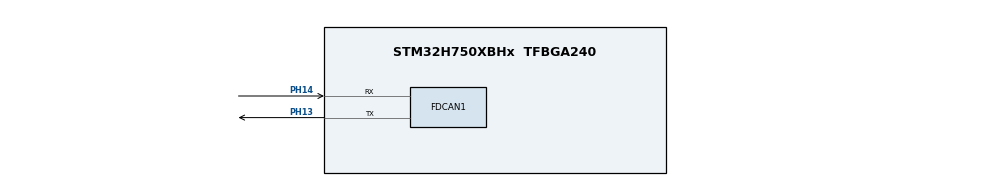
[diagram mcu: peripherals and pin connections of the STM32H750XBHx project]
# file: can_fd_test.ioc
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FDCAN1.AutoRetransmission=DISABLE
FDCAN1.CalculateBaudRateNominal=500000
FDCAN1.CalculateTimeBitNominal=2000
FDCAN1.CalculateTimeQuantumNominal=20.0
FDCAN1.DataPrescaler=2
FDCAN1.DataSyncJumpWidth=5
FDCAN1.DataTimeSeg1=19
FDCAN1.DataTimeSeg2=5
FDCAN1.FrameFormat=FDCAN_FRAME_FD_BRS
FDCAN1.Mode=FDCAN_MODE_EXTERNAL_LOOPBACK
FDCAN1.NominalPrescaler=1
FDCAN1.NominalSyncJumpWidth=13
FDCAN1.NominalTimeSeg1=86
FDCAN1.NominalTimeSeg2=13
FDCAN1.RxBufferSize=FDCAN_DATA_BYTES_12
FDCAN1.RxBuffersNbr=2
FDCAN1.RxFifo0ElmtSize=FDCAN_DATA_BYTES_12
FDCAN1.RxFifo0ElmtsNbr=1
FDCAN1.RxFifo1ElmtSize=FDCAN_DATA_BYTES_12
FDCAN1.RxFifo1ElmtsNbr=1
FDCAN1.StdFiltersNbr=10
FDCAN1.TransmitPause=ENABLE
FDCAN1.TxBuffersNbr=5
FDCAN1.TxElmtSize=FDCAN_DATA_BYTES_12
Mcu.Family=STM32H7
Mcu.Name=STM32H750XBHx
Mcu.Package=TFBGA240
NVIC.FDCAN1_IT0_IRQn=true\:0\:0\:false\:false\:true\:true\:true\:true
NVIC.FDCAN1_IT1_IRQn=true\:0\:0\:false\:false\:true\:true\:true\:true
NVIC.PriorityGroup=NVIC_PRIORITYGROUP_4
PB13.Signal=FDCAN2_TX
PH0-OSC_IN\ (PH0).Mode=HSE-External-Oscillator
PH0-OSC_IN\ (PH0).Signal=RCC_OSC_IN
PH1-OSC_OUT\ (PH1).Mode=HSE-External-Oscillator
PH1-OSC_OUT\ (PH1).Signal=RCC_OSC_OUT
PH13.Mode=FDCAN_Activate
PH13.Signal=FDCAN1_TX
PH14.Mode=FDCAN_Activate
PH14.Signal=FDCAN1_RX
ProjectManager.HeapSize=0x200
ProjectManager.StackSize=0x400
ProjectManager.TargetToolchain=STM32CubeIDE
RCC.ADCFreq_Value=80000000
RCC.APB1Freq_Value=100000000
RCC.APB2Freq_Value=100000000
RCC.APB3Freq_Value=100000000
RCC.APB4Freq_Value=100000000
RCC.CortexFreq_Value=400000000
RCC.D1PPRE=RCC_APB3_DIV2
RCC.D2PPRE1=RCC_APB1_DIV2
RCC.D2PPRE2=RCC_APB2_DIV2
RCC.D3PPRE=RCC_APB4_DIV2
RCC.DIVM1=2
RCC.DIVM2=5
RCC.DIVN1=64
RCC.DIVN2=32
RCC.DIVQ1=16
RCC.HCLKFreq_Value=200000000
RCC.HPRE=RCC_HCLK_DIV2
RCC.HSE_VALUE=25000000
RCC.PLL2FRACN=0
RCC.PLL3FRACN=0
RCC.PLLFRACN=0
RCC.PLLSourceVirtual=RCC_PLLSOURCE_HSE
RCC.SYSCLKFreq_VALUE=400000000
RCC.SYSCLKSource=RCC_SYSCLKSOURCE_PLLCLK
RCC.USBFreq_Value=50000000
VP_MEMORYMAP_VS_MEMORYMAP.Mode=CurAppReg
board=custom

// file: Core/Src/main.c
/* USER CODE BEGIN Header */
/**
  ******************************************************************************
  * @file           : main.c
  * @brief          : Main program body
  ******************************************************************************
  * @attention
  *
  * Copyright (c) 2024 STMicroelectronics.
  * All rights reserved.
  *
  * This software is licensed under terms that can be found in the LICENSE file
  * in the root directory of this software component.
  * If no LICENSE file comes with this software, it is provided AS-IS.
  *
  ******************************************************************************
  */
/* USER CODE END Header */
#include "main.h"
#include "fdcan.h"
#include "memorymap.h"
#include "gpio.h"

void SystemClock_Config(void);

/* USER CODE BEGIN 0 */
#define DEF_TX_DATA_LENGTH (12U)
FDCAN_FilterTypeDef sFilterConfig;
FDCAN_TxHeaderTypeDef TxHeader;
FDCAN_RxHeaderTypeDef RxHeader;
uint8_t TxData[DEF_TX_DATA_LENGTH] = {0x01, 0x02, 0x03, 0x04, 0x05, 0x06, 0x07, 0x08, 0x09, 0x0A, 0x0B, 0x0C};
uint8_t RxData_0[12];
uint8_t RxData_1[12];
uint8_t RxData_FIFO_0[12];
uint8_t new_buff_flag = 0;
uint8_t new_fifo_0_flag = 0;
uint8_t new_fifo_1_flag = 0;

uint8_t rx_data_ok = 0;
uint8_t rx_remote_ok = 0;
uint8_t rx_fifo_range_ok = 0;
uint8_t rx_fifo_mask_ok = 0;

void filterSet(void);
void txBufferSet(void);
void notificationSet(void);
void txbufferStart(void);
void newMessageCheckLoop(void);
/* USER CODE END 0 */

int main(void)
{

  /* MCU Configuration--------------------------------------------------------*/

  /* Reset of all peripherals, Initializes the Flash interface and the Systick. */
  HAL_Init();

  /* Configure the system clock */
  SystemClock_Config();

  /* Initialize all configured peripherals */
  MX_GPIO_Init();
  MX_FDCAN1_Init();
  /* USER CODE BEGIN 2 */
  /* USER CODE BEGIN 2 */
  filterSet();
  txBufferSet();

  HAL_FDCAN_Start(&hfdcan1);

  notificationSet();
  txbufferStart();

  /* USER CODE END 2 */

  /* Infinite loop */
  while (1)
  {

    /* USER CODE BEGIN 3 */
	  newMessageCheckLoop();
	  if(rx_data_ok == 1
	  			  && rx_remote_ok == 1
	  			  && rx_fifo_range_ok == 1)
	  {
		  rx_data_ok = 0;
		  rx_remote_ok = 0;
		  rx_fifo_range_ok = 0;
		  txbufferStart();
	  }
	  // mask error
//	  if(rx_data_ok == 1
//			  && rx_remote_ok == 1
//			  && rx_fifo_range_ok == 1
//			  && rx_fifo_mask_ok == 1)
//	  {
//		  rx_data_ok = 0;
//		  rx_remote_ok = 0;
//		  rx_fifo_range_ok = 0;
//		  rx_fifo_mask_ok = 0;
//		  txbufferStart();
//	  }
  }
  /* USER CODE END 3 */
}

void SystemClock_Config(void)
{
  RCC_OscInitTypeDef RCC_OscInitStruct = {0};
  RCC_ClkInitTypeDef RCC_ClkInitStruct = {0};

  /** Supply configuration update enable
  */
  HAL_PWREx_ConfigSupply(PWR_LDO_SUPPLY);

  /** Configure the main internal regulator output voltage
  */
  __HAL_PWR_VOLTAGESCALING_CONFIG(PWR_REGULATOR_VOLTAGE_SCALE1);

  while(!__HAL_PWR_GET_FLAG(PWR_FLAG_VOSRDY)) {}

  /** Initializes the RCC Oscillators according to the specified parameters
  * in the RCC_OscInitTypeDef structure.
  */
  RCC_OscInitStruct.OscillatorType = RCC_OSCILLATORTYPE_HSE;
  RCC_OscInitStruct.HSEState = RCC_HSE_ON;
  RCC_OscInitStruct.PLL.PLLState = RCC_PLL_ON;
  RCC_OscInitStruct.PLL.PLLSource = RCC_PLLSOURCE_HSE;
  RCC_OscInitStruct.PLL.PLLM = 2;
  RCC_OscInitStruct.PLL.PLLN = 64;
  RCC_OscInitStruct.PLL.PLLP = 2;
  RCC_OscInitStruct.PLL.PLLQ = 16;
  RCC_OscInitStruct.PLL.PLLR = 2;
  RCC_OscInitStruct.PLL.PLLRGE = RCC_PLL1VCIRANGE_3;
  RCC_OscInitStruct.PLL.PLLVCOSEL = RCC_PLL1VCOWIDE;
  RCC_OscInitStruct.PLL.PLLFRACN = 0;
  if (HAL_RCC_OscConfig(&RCC_OscInitStruct) != HAL_OK)
  {
    Error_Handler();
  }

  /** Initializes the CPU, AHB and APB buses clocks
  */
  RCC_ClkInitStruct.ClockType = RCC_CLOCKTYPE_HCLK|RCC_CLOCKTYPE_SYSCLK
                              |RCC_CLOCKTYPE_PCLK1|RCC_CLOCKTYPE_PCLK2
                              |RCC_CLOCKTYPE_D3PCLK1|RCC_CLOCKTYPE_D1PCLK1;
  RCC_ClkInitStruct.SYSCLKSource = RCC_SYSCLKSOURCE_PLLCLK;
  RCC_ClkInitStruct.SYSCLKDivider = RCC_SYSCLK_DIV1;
  RCC_ClkInitStruct.AHBCLKDivider = RCC_HCLK_DIV2;
  RCC_ClkInitStruct.APB3CLKDivider = RCC_APB3_DIV2;
  RCC_ClkInitStruct.APB1CLKDivider = RCC_APB1_DIV2;
  RCC_ClkInitStruct.APB2CLKDivider = RCC_APB2_DIV2;
  RCC_ClkInitStruct.APB4CLKDivider = RCC_APB4_DIV2;

  if (HAL_RCC_ClockConfig(&RCC_ClkInitStruct, FLASH_LATENCY_2) != HAL_OK)
  {
    Error_Handler();
  }
}

/* USER CODE BEGIN 4 */
void HAL_FDCAN_RxFifo0Callback(FDCAN_HandleTypeDef *hfdcan, uint32_t RxFifo0ITs)
{
	if(hfdcan->Instance == FDCAN1)
	{
		if((RxFifo0ITs & FDCAN_IT_RX_FIFO0_NEW_MESSAGE) != RESET)
		{
			new_fifo_0_flag = 1;
		}
	}
}

void HAL_FDCAN_RxFifo1Callback(FDCAN_HandleTypeDef *hfdcan, uint32_t RxFifo1ITs)
{
	if(hfdcan->Instance == FDCAN1)
	{
		if((RxFifo1ITs & FDCAN_IT_RX_FIFO1_NEW_MESSAGE) != RESET)
		{
			new_fifo_1_flag = 1;
		}
	}
}

void HAL_FDCAN_RxBufferNewMessageCallback(FDCAN_HandleTypeDef *hfdcan)
{
	if(hfdcan->Instance == FDCAN1)
	{
		new_buff_flag = 1;
	}
}

void filterSet(void)
{
	/* Configure standard ID reception filter to Rx buffer 0 */
	sFilterConfig.IdType = FDCAN_STANDARD_ID;
	sFilterConfig.FilterIndex = 0;
	sFilterConfig.FilterType = FDCAN_FILTER_DUAL;
	sFilterConfig.FilterConfig = FDCAN_FILTER_TO_RXBUFFER;
	sFilterConfig.FilterID1 = 0x100;
	sFilterConfig.FilterID2 = 0; // This parameter is ignored if FilterConfig is set to FDCAN_FILTER_TO_RXBUFFER.
	sFilterConfig.RxBufferIndex = FDCAN_RX_BUFFER0;
	HAL_FDCAN_ConfigFilter(&hfdcan1, &sFilterConfig);

	/* Configure standard ID reception filter to Rx buffer 1 */
	sFilterConfig.IdType = FDCAN_STANDARD_ID;
	sFilterConfig.FilterIndex = 1;
	sFilterConfig.FilterType = FDCAN_FILTER_DUAL;
	sFilterConfig.FilterConfig = FDCAN_FILTER_TO_RXBUFFER;
	sFilterConfig.FilterID1 = 0x101;
	sFilterConfig.FilterID2 = 0; // This parameter is ignored if FilterConfig is set to FDCAN_FILTER_TO_RXBUFFER.
	sFilterConfig.RxBufferIndex = FDCAN_RX_BUFFER1;
	HAL_FDCAN_ConfigFilter(&hfdcan1, &sFilterConfig);

	/* Configure standard ID reception filter to Rx buffer 1 */
	sFilterConfig.IdType = FDCAN_STANDARD_ID;
	sFilterConfig.FilterIndex = 2;
	sFilterConfig.FilterType = FDCAN_FILTER_RANGE;
	sFilterConfig.FilterConfig = FDCAN_FILTER_TO_RXFIFO0;
	sFilterConfig.FilterID1 = 0x102;
	sFilterConfig.FilterID2 = 0x105; // This parameter is ignored if FilterConfig is set to FDCAN_FILTER_TO_RXBUFFER.
	// ignored buffer index in fifo mode
	// sFilterConfig.RxBufferIndex = FDCAN_RX_BUFFER2;

	/* Configure standard ID reception filter to Rx buffer 2 */
	sFilterConfig.IdType = FDCAN_STANDARD_ID;
	sFilterConfig.FilterIndex = 3;
	sFilterConfig.FilterType = FDCAN_FILTER_MASK;
	sFilterConfig.FilterConfig = FDCAN_FILTER_TO_RXFIFO1;
	sFilterConfig.FilterID1 = 0x106;
	sFilterConfig.FilterID2 = 0x10F; // This parameter is ignored if FilterConfig is set to FDCAN_FILTER_TO_RXBUFFER.

	HAL_FDCAN_ConfigFilter(&hfdcan1, &sFilterConfig);
	/* Configure global filter */
	HAL_FDCAN_ConfigGlobalFilter(&hfdcan1,
								FDCAN_ACCEPT_IN_RX_FIFO0,
								FDCAN_REJECT,
								FDCAN_FILTER_REMOTE,
								FDCAN_REJECT_REMOTE);
}

void txBufferSet(void)
{
	/* Configure Tx buffer message */
	TxHeader.Identifier = 0x100;
	TxHeader.IdType = FDCAN_STANDARD_ID;
	TxHeader.TxFrameType = FDCAN_DATA_FRAME;
	TxHeader.DataLength = FDCAN_DLC_BYTES_12;
	TxHeader.ErrorStateIndicator = FDCAN_ESI_ACTIVE;
	TxHeader.BitRateSwitch = FDCAN_BRS_ON;
	TxHeader.FDFormat = FDCAN_FD_CAN;
	TxHeader.TxEventFifoControl = FDCAN_NO_TX_EVENTS;
	TxHeader.MessageMarker = 0x00; // Ignore because FDCAN_NO_TX_EVENTS
	HAL_FDCAN_AddMessageToTxBuffer(&hfdcan1, &TxHeader, TxData, FDCAN_TX_BUFFER0);

	/* Configure Tx buffer message */
	TxHeader.Identifier = 0x101;
	TxHeader.IdType = FDCAN_STANDARD_ID;
	TxHeader.TxFrameType = FDCAN_REMOTE_FRAME;
	TxHeader.DataLength = FDCAN_DLC_BYTES_12;
	TxHeader.ErrorStateIndicator = FDCAN_ESI_ACTIVE;
	TxHeader.BitRateSwitch = FDCAN_BRS_ON;
	TxHeader.FDFormat = FDCAN_FD_CAN;
	TxHeader.TxEventFifoControl = FDCAN_NO_TX_EVENTS;
	TxHeader.MessageMarker = 0x00; // Ignore because FDCAN_NO_TX_EVENTS
	HAL_FDCAN_AddMessageToTxBuffer(&hfdcan1, &TxHeader, TxData, FDCAN_TX_BUFFER1);

	for(int i = 0; i < DEF_TX_DATA_LENGTH; i++)
	{
		TxData[i] = i;
	}
	/* Configure Tx buffer message */
	TxHeader.Identifier = 0x103;
	TxHeader.IdType = FDCAN_STANDARD_ID;
	TxHeader.TxFrameType = FDCAN_DATA_FRAME;
	TxHeader.DataLength = FDCAN_DLC_BYTES_12;
	TxHeader.ErrorStateIndicator = FDCAN_ESI_ACTIVE;
	TxHeader.BitRateSwitch = FDCAN_BRS_ON;
	TxHeader.FDFormat = FDCAN_FD_CAN;
	TxHeader.TxEventFifoControl = FDCAN_NO_TX_EVENTS;
	TxHeader.MessageMarker = 0x00; // Ignore because FDCAN_NO_TX_EVENTS
	HAL_FDCAN_AddMessageToTxBuffer(&hfdcan1, &TxHeader, TxData, FDCAN_TX_BUFFER2);

	for(int i = 0; i < DEF_TX_DATA_LENGTH; i++)
	{
		TxData[i] = i * 2;
	}
	/* Configure Tx buffer message */
	TxHeader.Identifier = 0x106;
	TxHeader.IdType = FDCAN_STANDARD_ID;
	TxHeader.TxFrameType = FDCAN_DATA_FRAME;
	TxHeader.DataLength = FDCAN_DLC_BYTES_12;
	TxHeader.ErrorStateIndicator = FDCAN_ESI_ACTIVE;
	TxHeader.BitRateSwitch = FDCAN_BRS_ON;
	TxHeader.FDFormat = FDCAN_FD_CAN;
	TxHeader.TxEventFifoControl = FDCAN_NO_TX_EVENTS;
	TxHeader.MessageMarker = 0x00; // Ignore because FDCAN_NO_TX_EVENTS
	HAL_FDCAN_AddMessageToTxBuffer(&hfdcan1, &TxHeader, TxData, FDCAN_TX_BUFFER3);
}

void notificationSet(void)
{
	HAL_FDCAN_ActivateNotification(&hfdcan1, FDCAN_IT_RX_BUFFER_NEW_MESSAGE, 0);
	HAL_FDCAN_ActivateNotification(&hfdcan1, FDCAN_IT_RX_BUFFER_NEW_MESSAGE, 1);

	// ignored buffer index in fifo mode
	HAL_FDCAN_ActivateNotification(&hfdcan1, FDCAN_IT_RX_FIFO0_NEW_MESSAGE | FDCAN_IT_RX_FIFO1_NEW_MESSAGE, 0);
}

void txbufferStart(void)
{
	HAL_FDCAN_EnableTxBufferRequest(&hfdcan1, FDCAN_TX_BUFFER0);
	while(HAL_FDCAN_IsTxBufferMessagePending(&hfdcan1, FDCAN_TX_BUFFER0));

	HAL_FDCAN_EnableTxBufferRequest(&hfdcan1, FDCAN_TX_BUFFER1);
	while(HAL_FDCAN_IsTxBufferMessagePending(&hfdcan1, FDCAN_TX_BUFFER1));

	HAL_FDCAN_EnableTxBufferRequest(&hfdcan1, FDCAN_TX_BUFFER2);
	while(HAL_FDCAN_IsTxBufferMessagePending(&hfdcan1, FDCAN_TX_BUFFER2));
//
//	HAL_FDCAN_EnableTxBufferRequest(&hfdcan1, FDCAN_TX_BUFFER3);
//	while(HAL_FDCAN_IsTxBufferMessagePending(&hfdcan1, FDCAN_TX_BUFFER2));
}

void newMessageCheckLoop(void)
{
	if(new_buff_flag == 1)
	{
		if(HAL_FDCAN_IsRxBufferMessageAvailable(&hfdcan1, FDCAN_RX_BUFFER0) == 1)
		{
			HAL_FDCAN_GetRxMessage(&hfdcan1, FDCAN_RX_BUFFER0, &RxHeader, RxData_0);
			if(RxHeader.RxFrameType == FDCAN_DATA_FRAME)
			{
				// data frame checker
				rx_data_ok = 1;
			}
		}
		if(HAL_FDCAN_IsRxBufferMessageAvailable(&hfdcan1, FDCAN_RX_BUFFER1) == 1)
		{
			HAL_FDCAN_GetRxMessage(&hfdcan1, FDCAN_RX_BUFFER1, &RxHeader, RxData_1);
			if(RxHeader.RxFrameType == FDCAN_REMOTE_FRAME)
			{
				// remote frame checker
				rx_remote_ok = 1;
			}
		}
		new_buff_flag = 0;
	}
	if(new_fifo_0_flag == 1)
	{
		// cannot use fdcan_isrxbuffermessageavailable
		HAL_FDCAN_GetRxMessage(&hfdcan1, FDCAN_RX_FIFO0, &RxHeader, RxData_FIFO_0);

		rx_fifo_range_ok = 1;
		new_fifo_0_flag = 0;
	}
	if(new_fifo_1_flag == 1)
	{
		rx_fifo_mask_ok = 1;
		new_fifo_1_flag = 0;
	}
}
/* USER CODE END 4 */

void Error_Handler(void)
{
  __disable_irq();
  while (1)
  {
  }
}
